# FM33L0XX register map
File version: 1.0
CPU: SC000 r1p0, little endian, no MPU, no FPU, 3 interrupt priority bits
Registers are 32-bit, read-write, reset 0x0 unless marked. A register's access mark holds for its fields unless they carry their own. Offsets are from the block's base; [hi:lo] are bit positions.

## FLS — NVMIF Registers
Base 0x40001000
0x00 FLS_RDCR — FLASH read control register
  [1:0] WAIT — wait cycle at flash resd
    0=ZERO (0 wait cycle); 1=ONE (1 wait cycle); 2=TWO (2 wait cycle); 3=ZERO (0 wait cycle)
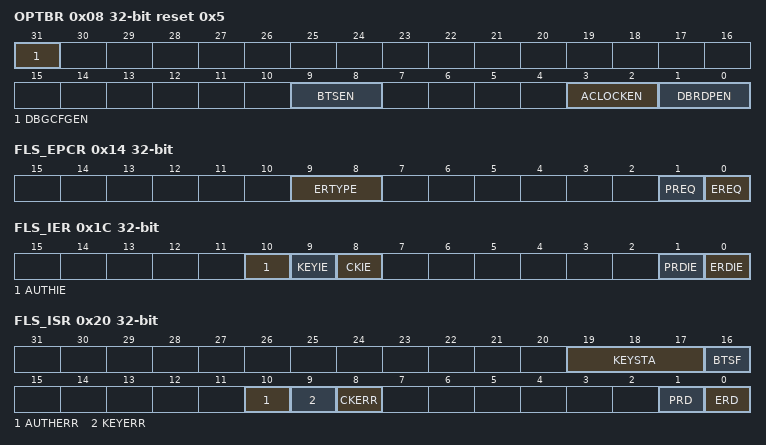
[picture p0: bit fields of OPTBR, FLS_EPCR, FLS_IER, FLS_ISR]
0x08 OPTBR ro reset 0x5
  [31] DBGCFGEN — DEBUG CONFIG REGISTER ENABLE
    0=ENABLE (DEBUG CONFIG REGISTER ENABLE); 1=DISABLE (DEBUG CONFIG REGISTER DISABLE)
  [9:8] BTSEN — BootSwap Enable
    0=DISABLE; 1=DISABLE; 2=ENABLE; 3=DISABLE
  [3:2] ACLOCKEN
    0=DISABLE (ACLOCK DISABLE); 1=DISABLE (ACLOCK DISABLE); 2=ENABLE (ACLOCK ENABLE); 3=DISABLE (ACLOCK DISABLE)
  [1:0] DBRDPEN — debug port read protect
    0=DISABLE (debug port read protect disable); 1=DISABLE (debug port read protect disable); 2=ENABLE (debug port read protect enable); 3=DISABLE (debug port read protect disable)
0x0C FLS_ACLOCK reset 0xFFFFFFFF — ACLOCK config reister1
0x14 FLS_EPCR — erase & prog config register
  [9:8] ERTYPE — erase tyre
    0=SECTOR (Sector Erase); 2=CHIP (Chip Erase); 3=SECTOR (Sector Erase)
  [1] PREQ wo — Program Request
  [0] EREQ write_only — Erase Request
0x18 FLS_KEY — FLASH KEY REGISTER
0x1C FLS_IER — FLASH IE
  [10] AUTHIE — AUTH ERR IE
  [9] KEYIE — FLASH KEY ERR IE
  [8] CKIE — CLOCK ERR IE
  [1] PRDIE — PROG FINISH IE
  [0] ERDIE — ERASE FINISH IE
0x20 FLS_ISR — FLASH IF
  [19:17] KEYSTA ro — KEY STATE
    0=IDLE; 1=CHIP_ERASE_UNLOCK; 2=SECTOR_ERASE_UNLOCK; 3=PROG_UNLOCK; 4=KEY_ERR
  [16] BTSF ro — BootSwap FLAG
    0=BOOT_0000H; 1=BOOT_2000H
  [10] AUTHERR — AUTH ERR IF
  [9] KEYERR — KEY ERR IF
  [8] CKERR — CLK ERR IF
  [1] PRD — PROG DONE IF
  [0] ERD — ERASE DONE IF

## CRC
Base 0x40010000
0x00 CRC_DR reset 0xFFFFFFFF — CRC DATA REGISTER
  [31:0] DR — CRCDR
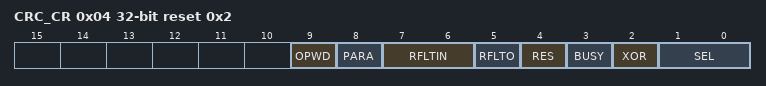
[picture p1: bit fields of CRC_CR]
0x04 CRC_CR reset 0x2 — CRC CONTROL REGISTER
  [9] OPWD — WORD_OPRATE_EN
    0=DISABLE; 1=ENABLE
  [8] PARA
    0=DISABLE; 1=ENABLE
  [7:6] RFLTIN — input reverse
    0=NO-REFLECT; 1=BYTE-REFLECT; 2=HALF_WORD_REFLECT; 3=WORD_REFLECT
  [5] RFLTO — output reverse
  [4] RES ro — result is zero
  [3] BUSY ro
  [2] XOR — OUTPUT XOR
  [1:0] SEL — MODE SELECT
    0=CRC32; 1=CRC16; 2=CRC8; 3=CRC7
0x08 CRCLFSR reset 0xFFFFFFFF
  [31:0] LFSR
0x0C CRC_XOR
  [31:0] CRCXOR
0x10 FLS_CR — FLASH CRC ENABLE
  [0] FLSCRCEN
    0=DISABLE; 1=ENABLE
0x14 CRC_FLS_AD — FLASH CRC ADDR
  [14:0] FLSAD
0x18 CRC_FLS_SIZE — FLASH CRC SIZE
  [14:0] FLSS — SIZE = (FLSS+1)*4
0x1C CRC_POLY reset 0x1021

## LPUART0 — LPUART0 Registers
Base 0x40010400
Same registers: LPUART1 0x40010420
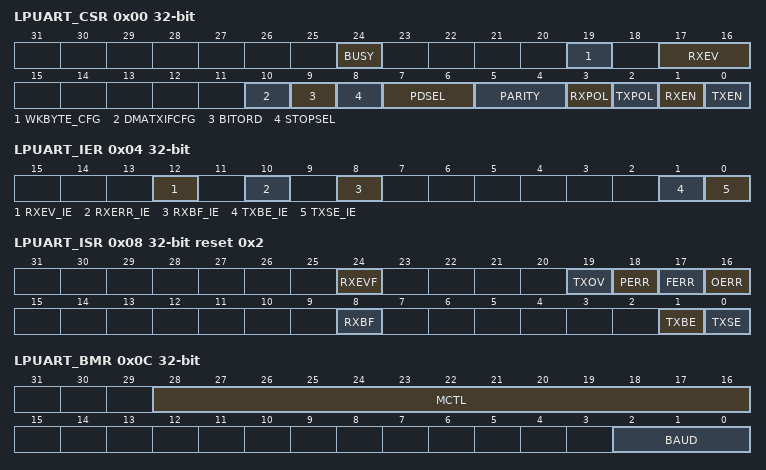
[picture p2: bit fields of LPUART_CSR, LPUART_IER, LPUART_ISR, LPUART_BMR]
0x00 LPUART_CSR — LPUART Config
  [24] BUSY ro — LPUARTx BUSY
    0=NO BUSY; 1=BUSY
  [19] WKBYTE_CFG — LPUARTx WKBYTE_CFG
    0=NOT CHECK; 1=CHECK
  [17:16] RXEV — LPUARTx RXEV
    0=START; 1=1 BYTE RECEIVE; 2=RECEIVE MATCH; 3=RXD FALLING
  [10] DMATXIFCFG — LPUART DMATXIFCFG
    0=DEPENDS; 1=ENABLE
  [9] BITORD — LPUARTx BITORD
    0=1BIT (1 STOPBIT); 1=2BIT (2 STOPBIT)
  [8] STOPSEL — STOP BIT select
    0=1BIT (1 STOPBIT); 1=2BIT (2 STOPBIT)
  [7:6] PDSEL — LPUART PDSEL
    0=7 BIT (UARx 7 BIT); 1=8 BIT (UARx 8 BIT); 2=9 BIT (UARx 9 BIT)
  [5:4] PARITY — LPUARTx PARITY
    0=NO PARITY (UARx NO PARITY BIT); 1=PARITY EVEN (UARx PARITY EVEN); 2=PARITY ODD (UARx PARITY ODD)
  [3] RXPOL — LPUARTx RXPOL
    0=NORMAL (UARx RX NORMAL); 1=REVERSE (UARx RX REVERSE)
  [2] TXPOL — LPUARTx TXPOL
    0=NORMAL (UARx TX NORMAL); 1=REVERSE (UARx TX REVERSE)
  [1] RXEN — RX ENABLE
  [0] TXEN — TX ENable
0x04 LPUART_IER — LPUARTIE Config
  [all] fields
    0=DISABLE; 1=ENABLE
  [12] RXEV_IE — LPUARTx RXEV_IE
  [10] RXERR_IE — LPUARTx RXERR_IE
  [8] RXBF_IE — LPUARTx RXBF_IE
  [1] TXBE_IE — LPUARTx TXBE_IE
  [0] TXSE_IE — LPUARTx TXSE_IE
0x08 LPUART_ISR reset 0x2 — LPUART0IF Status
  [all] fields
    0=DISABLE; 1=ENABLE
  [24] RXEVF — LPUARTx RXEVF
  [19] TXOV — LPUARTx TXOV
  [18] PERR — LPUARTx PERR
  [17] FERR — LPUARTx FERR
  [16] OERR — LPUARTx OERR
  [8] RXBF — LPUARTx RXBF
  [1] TXBE — LPUARTx TXBE
  [0] TXSE — LPUARTx TXSE
0x0C LPUART_BMR
  [28:16] MCTL
  [2:0] BAUD — LPUARTx BAUD
    0=9600; 1=4800; 2=2400; 3=1200; 4=600; 5=300; 6=300; 7=300
0x10 LPUART_RXBUF
  [8:0] RXBUF
0x14 LPUART_TXBUF
  [8:0] TXBUF — UARTx TXBUF
0x18 LPUART_DMR
  [8:0] MATD — LPUART0 MATD
